# YTM32B1MD2 register map
Vendor: YTMicro; File version: 1.0
CPU: CM33 r0p4, little endian, MPU, FPU, 2 interrupt priority bits
Registers are 32-bit, read-write, reset 0x0 unless marked. A register's access mark holds for its fields unless they carry their own. Offsets are from the block's base; [hi:lo] are bit positions; {n}, {i} and the like mark numbered series; 'fields as' and 'values as' point back to an identical list.

## UART0 — UART module with LIN mode support
Base 0x4001B000; register names take the prefix UART0_
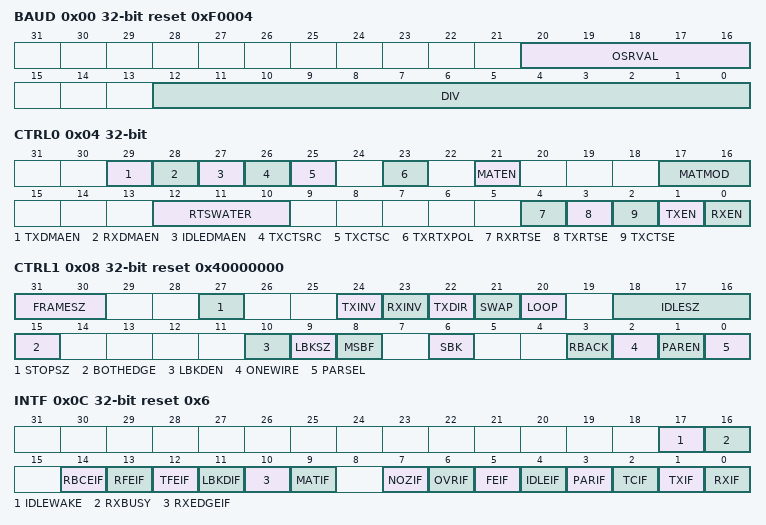
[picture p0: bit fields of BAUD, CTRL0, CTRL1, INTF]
0x00 BAUD reset 0xF0004
  [20:16] OSRVAL — Over sample config, only support update when module disabled
    0=Over sample value is 16; {v}=Over sample value is {v+1}, need to set BOTHEDGE bit (v=3..6); {v}=Over sample value is {v+1} (v=7..31)
  [12:0] DIV — Function clock divider to generate sample baudrate clock
0x04 CTRL0
  [29] TXDMAEN — TX DATA request DMA enable when TX fifo less than watermark or buff empty
    0=DMA request disabled; 1=DMA request enabled
  [28] RXDMAEN — RX DATA request DMA enable when RX fifo great than watermark or buff full
    0=DMA request disabled; 1=DMA request enabled
  [27] IDLEDMAEN — Control bit to control weather DMA request generated after UART idle
    0=UART IDLE DMA request disable; 1=UART IDLE DMA request enable
  [26] TXCTSRC — Configures the source of the CTS input.
    0=TX CTS source is from TX CTS pin; 1=An internal connection to the receiver address match result
  [25] TXCTSC — Configures whether the CTS state or input is checked or sampled at the start of each character or only when the transmitter is idle.
    0=Sampled at the start of each character; 1=Sampled when the transmitter is idle
  [23] TXRTXPOL — Controls the polarity of the transmitter RTS. This field does not affect the polarity of the receiver RTS that remains negated in the active-low state unless MODIR[TXRTSE] = 1. You must change the value of this field only when the transmitter is disabled.
    0=TX RTS is active low; 1=TX RTS is active high
  [21] MATEN — Setting this bit will enable RX data match logic in UART
    0=UART data match disable; 1=UART data match enable
  [17:16] MATMOD
    0=Address match wakeup (the most significant bit of address must be 1); 1=Address match and line idle event detected wakeup; 2=Match on and match off
  [12:10] RTSWATER — Configures the assertion and negation of the receiver's RTS_B output. The receiver's RTS_B output negates when the number of empty words in the receive FIFO is less or equal to the value of this field. If this field is 0, the RTS_B pin negates when the receive FIFO is full. For the purpose of receive RTS_B generation, the number of words in the receive FIFO updates when a start bit is detected. This supports additional latency between RTS_B negation and the external transmitter ceasing transmission. If both receive RTS_B and address or data matching is enabled, RTS_B could assert at the end of a character if there exists no match. You must change the value of this field only when the receiver is disabled.
  [4] RXRTSE — Allows the RTS output to control the CTS input of the transmitting device to prevent receiver overrun. You must change the value of this field only when the receiver is disabled. If the value of this field = 0, the receiver has no effect on RTS. If the value of this field = 1, RTS is deasserted if STS[RXIF] = 1 or a start bit is detected that causes STS[RXIF] to become 1. RTS is asserted if STS[RXIF] = 0 and has not detected a start bit that causes STS[RXIF] to become 1. If fifo is not used, this bit is determined based on whether the buffer is empty.
    0=RX RTS is disabled; 1=RX RTS is enabled
  [3] TXRTSE — Controls the operation of RTS before and after a transmission. You must change the value of this field only when the transmitter is disabled. When the value of this field = 1, a character is placed into an empty transmit shift register. RTS asserts 1-bit time before the start bit is transmitted and deasserts 1-bit time after all characters in the transmitter FIFO and shift register are completely sent, including the last stop bit. If the value of this field = 0, the transmitter has no effect on RTS.
    0=RX RTS is disabled; 1=RX RTS is enabled
  [2] TXCTSE — Enables the operation of the transmitter. You can write 1 to this field irrespective of the states of CTRL0[TXRTSE] and CTRL0[RXRTSE]. If the value of this field = 1, the transmitter checks the state of the CTS signal each time it is ready to send a character. If CTS is asserted, the character is sent. If CTS is deasserted, the signal TXD remains in the mark state and transmission is delayed until CTS is asserted. Changes in CTS, when a character is being sent, do not affect its transmission.
    0=TX CTS is disabled; 1=TX CTS is enabled
  [1] TXEN
    0=TX logic is disabled; 1=TX logic is enabled
  [0] RXEN
    0=RX logic is disabled; 1=RX logic is enabled
0x08 CTRL1 reset 0x40000000
  [31:30] FRAMESZ — Control bit count in one frame transfer
    {v}={v+7}-bit data mode (v=0..3)
  [27] STOPSZ — Stop bit size selection
    0=1-bit stop; 1=2-bit stop
  [24] TXINV — Invert TX line output, this bit will change data, start, stop, break and idle polarity.
    0=TX data line is not inverted; 1=TX data line is inverted
  [23] RXINV — Invert RX line input, this bit will change data, start, stop, break and idle polarity.
    0=RX data line is not inverted; 1=RX data line is inverted
  [22] TXDIR — Selection TX line direction when using single line mode
    0=TX line is data input under single line mode; 1=TX line is data output under single line mode
  [21] SWAP — Swap TX and RX lines
    0=TX RX line under normal mode; 1=Swap TX and RX lines, data input on TX, data output to RX
  [20] LOOP — Internal loop back test mode enable
    0=Internal loop back test mode disable; 1=Internal loop back test mode enable, data input from output line TX directly
  [18:16] IDLESZ — IDLE detection bytes size
    0=1 idle character; 1=2 idle character; 2=4 idle character; 3=8 idle character; 4=16 idle character; 5=32 idle character; 6=64 idle character; 7=128 idle character
  [15] BOTHEDGE — Setting this bit allows uart sample data on both rising and falling of baudrate clock. This bit need to set when BAUD[OSRVAL] less than 7, only support update when RX logic disabled.
  [10] LBKDEN — LBKDEN enable UART detection LIN break, and the break character whether it is stored in RX FIFO depends on bit LBKWRFIFOEN.
    0=LIN break detection is disabled; 1=LIN break detection is enabled
  [9] LBKSZ
    0=Break character is transmitted with length of 9 to 13 bit times; 1=Break character is transmitted with length of 12 to 15 bit times
  [8] MSBF — Setting this bit will change following data transfer shift order
    0=LSB is shifted out first after start bit; 1=MSB is shifted out first after start bit
  [6] SBK — Send LIN break out, when SBK bit set, UART will send out LIN break continuously until SBK bit cleared.
    0=Normal mode; 1=Send out continuous LIN break
  [3] RBACK — Setting this bit will enable UART read back function, it will set RXEN at same time,disable RXEN will also disable this bit
    0=Read back function disable; 1=Read back function enable
  [2] ONEWIRE — Setting this bit will enable UART one wire mode
    0=One wire mode disable; 1=One wire mode enable
  [1] PAREN — Setting this bit will enable UART hardware parity check/generation on both RX and TX
    0=Hardware parity feature disabled; 1=Hardware parity feature enabled on RX and TX
  [0] PARSEL — Valid when PAREN bit set, PARSEL control UART use odd or even parity check/generation
    0=Even parity; 1=Odd parity
0x0C INTF reset 0x6
  [17] IDLEWAKE ro
    0=IDLE wake up not detected; 1=IDLE wake up event detected
  [16] RXBUSY ro
    0=RX line idle and wait for data; 1=RX is receiving data
  [14] RBCEIF — Read back compare error event occurs during readback comparisons happened will set this bit
    0=No Readback compare failure detected; 1=Readback compare failure event occurs detected
  [13] RFEIF — RX FIFO underflow happened, read RX FIFO when RX FIFO empty will set this bit
    0=No RX FIFO underflow detected; 1=RX FIFO underflow detected
  [12] TFEIF — TX FIFO overflow happened, write TX FIFO when RX FIFO full will set this bit
    0=No TX FIFO overflow detected; 1=TX FIFO overflow detected
  [11] LBKDIF
    0=LIN break not detected; 1=LIN break detected
  [10] RXEDGEIF
    0=UART RX active edge not detected; 1=UART RX active edge detected
  [9] MATIF
    0=UART RX data match not detected; 1=UART RX data match detected
  [7] NOZIF
    0=UART RX noise not detected; 1=UART RX noise detected
  [6] OVRIF — UART received new data when RX FIFO or buffer is full will set this bit ewline ote{User have to clear this bit before receiving new data after RX FIFO or buffer not full.}
    0=UART RX overrun not detected; 1=UART RX overrun detected, and no new data will be stored
  [5] FEIF — FEIF set when no valid STOP bit received after data phase
    0=UART RX frame error not detected; 1=UART RX frame error detected
  [4] IDLEIF — IDLE set when UART RX line keeps high time longer than idle condition setting. after bit cleared, idle flag won't set unless new data received.
    0=UART RX idle not detected; 1=UART RX idle detected
  [3] PARIF — Parity check error happened when hardware calculated parity bit not match received.
    0=UART RX data parity error not detected; 1=UART RX data parity error detected
  [2] TCIF ro — TCIF cleared when write TX data and TX start send data, TCIF set when TX line idle
    0=UART transmitter is busy and transmitting data; 1=UART transmitter is idle
  [1] TXIF ro — Indicates words in TX FIFO is equal or less than TX FIFO watermark setting
    0=Word in TX FIFO is greater than watermark; 1=Word in TX FIFO is equal or less than watermark, request to write new data
  [0] RXIF ro — Indicates words in RX FIFO is greater than RX FIFO watermark setting
    0=Word in RX FIFO is equal or less than watermark, or buffer full when fifo not enabled; 1=Word in RX FIFO is greater than watermark, or buffer full when fifo not enabled, should read data register
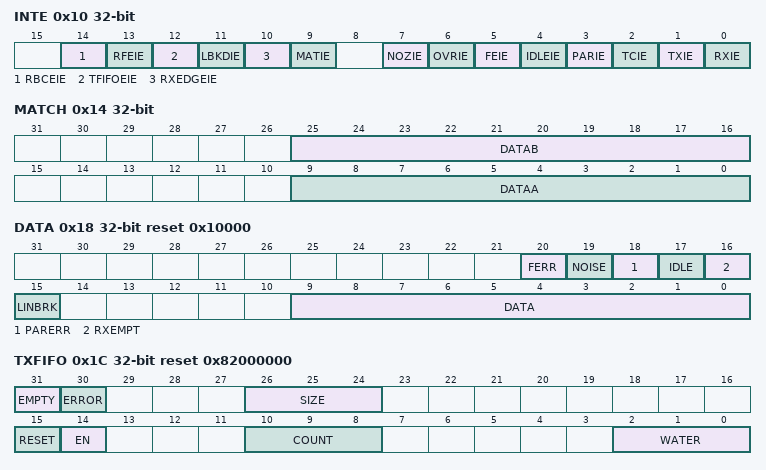
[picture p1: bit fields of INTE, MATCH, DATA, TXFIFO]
0x10 INTE
  [14] RBCEIE
    0=Readback compare interrupt disabled; 1=Readback compare interrupt enabled
  [13] RFEIE
    0=Interrupt disabled; 1=Interrupt enabled
  [12] TFIFOEIE
    0=Interrupt disabled; 1=Interrupt enabled
  [11] LBKDIE
    0=Interrupt disabled; 1=Interrupt enabled
  [10] RXEDGEIE
    0=Interrupt disabled; 1=Interrupt enabled
  [9] MATIE
    0=Interrupt disabled; 1=Interrupt enabled
  [7] NOZIE
    0=Interrupt disabled; 1=Interrupt enabled
  [6] OVRIE
    0=Interrupt disabled; 1=Interrupt enabled
  [5] FEIE
    0=Interrupt disabled; 1=Interrupt enabled
  [4] IDLEIE
    0=Interrupt disabled; 1=Interrupt enabled
  [3] PARIE
    0=Interrupt disabled; 1=Interrupt enabled
  [2] TCIE
    0=Interrupt disabled; 1=Interrupt enabled
  [1] TXIE
    0=Interrupt disabled; 1=Interrupt enabled
  [0] RXIE
    0=Interrupt disabled; 1=Interrupt enabled
0x14 MATCH
  [25:16] DATAB — Data match compare value B
  [9:0] DATAA — Data match compare value A
0x18 DATA reset 0x10000 — Reading DATA register will return received data in RX FIFO, writing DATA register will push data to TX FIFO and waiting for transfer. ote{This register only support 32-bit access.}
  [20] FERR ro — Received data has frame error (STOP bit not valid)
    0=UART RX data normal; 1=UART RX data has frame error
  [19] NOISE ro — Received data has noise on RX line
    0=UART RX data normal; 1=UART RX data has noise
  [18] PARERR ro — Parity error flag
    0=UART RX data has no parity error; 1=UART RX data has parity error
  [17] IDLE ro
    0=UART RX line is not idle; 1=UART RX line is idle
  [16] RXEMPT ro
    0=UART RX FIFO is not empty, reading data is valid; 1=UART RX FIFO is empty, reading data is invalid
  [15] LINBRK wo — Writing LINBRK bit will let UART send out LIN break instead of DATA
  [9:0] DATA — Reading DATA field will return data in RX FIFO, writing DATA field will push data to TX FIFO
0x1C TXFIFO reset 0x82000000
  [31] EMPTY ro — TX FIFO empty, asserts when there is no data in the TX FIFO.
    1=TX FIFO is empty
  [30] ERROR ro — Writing TX FIFO with TX FIFO full will set ERROR bit
    1=TX FIFO has overflow error
  [26:24] SIZE ro — Available TX FIFO Size is 2^SIZE words
  [15] RESET wo — Reset TX FIFO address pointer
  [14] EN
    0=FIFO is not enabled, data buffer is used; 1=FIFO is enabled
  [10:8] COUNT ro — TX FIFO current data count
  [2:0] WATER — TXIF set when words count in TX FIFO equal or less than watermark
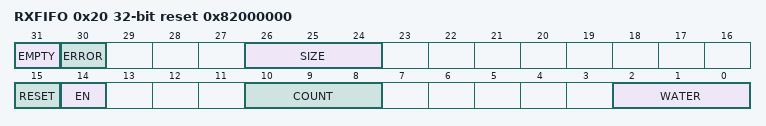
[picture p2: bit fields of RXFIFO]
0x20 RXFIFO reset 0x82000000
  [31] EMPTY ro — RX FIFO empty, asserts when there is no data in the RX FIFO.
  [30] ERROR ro — Reading RX FIFO with RX FIFO empty will set ERROR bit
    1=RX FIFO has underflow error
  [26:24] SIZE ro — Available RX FIFO Size is 2^SIZE words
  [15] RESET wo — Reset RX FIFO address pointer
  [14] EN
    values as TXFIFO.EN
  [10:8] COUNT — RX FIFO current data count
  [2:0] WATER — RXIF set when words count in RX FIFO greater than watermark

## UART1 — UART module with LIN mode support
Base 0x4001C000; register names take the prefix UART1_
Registers as UART0.

## UART2 — UART module with LIN mode support
Base 0x4001D000; register names take the prefix UART2_
Registers as UART0.
